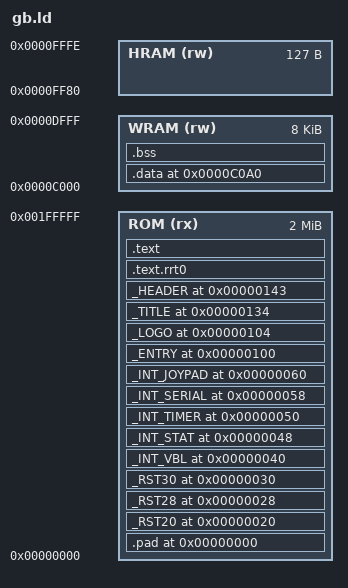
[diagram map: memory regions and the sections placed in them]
/* Game Boy (SM83) linker script for ld.lld + rrt0 */

ENTRY(_reset)

MEMORY {
    ROM  (rx) : ORIGIN = 0x0000, LENGTH = 0x200000  /* 2MB max (MBC5) */
    WRAM (rw) : ORIGIN = 0xC000, LENGTH = 0x2000
    HRAM (rw) : ORIGIN = 0xFF80, LENGTH = 0x007F
}

SECTIONS {
    .pad 0x0000 : { FILL(0xFF); . = 0x0020; } > ROM

    _RST20      (0x0020) : { KEEP(*(_RST20)) } > ROM
    _RST28      (0x0028) : { KEEP(*(_RST28)) } > ROM
    _RST30      (0x0030) : { KEEP(*(_RST30)) } > ROM

    _INT_VBL    (0x0040) : { KEEP(*(_INT_VBL)) } > ROM
    _INT_STAT   (0x0048) : { KEEP(*(_INT_STAT)) } > ROM
    _INT_TIMER  (0x0050) : { KEEP(*(_INT_TIMER)) } > ROM
    _INT_SERIAL (0x0058) : { KEEP(*(_INT_SERIAL)) } > ROM
    _INT_JOYPAD (0x0060) : { KEEP(*(_INT_JOYPAD)) } > ROM

    _ENTRY      (0x0100) : { KEEP(*(_ENTRY)) } > ROM
    _LOGO       (0x0104) : { KEEP(*(_LOGO)) } > ROM
    _TITLE      (0x0134) : { KEEP(*(_TITLE)) } > ROM
    _HEADER     (0x0143) : { KEEP(*(_HEADER)) } > ROM

    .text.rrt0 : { KEEP(*(.text.rrt0)) } > ROM

    /* Banked sections must be claimed before the resident .text glob below, as
       the linker assigns each input section to the first output section that
       matches. They carry an explicit VMA and AT(), so they leave the resident
       location counter alone; __resident_lma saves it for the .text below.
       gb_banked.ld is generated by gb-bank-pack, empty when nothing is banked,
       and found through the -L path cargo-gb passes. */
    __resident_lma = .;
    INCLUDE "gb_banked.ld"

    /* Without the explicit AT(), the preceding banked sections leave the load
       counter in a high bank and the flat binary overlaps. */
    .text __resident_lma : AT(__resident_lma) {
        *(.text .text.*)
        *(.rodata .rodata.*)
    } > ROM

    /* The LMA follows .text in bank 0, where rrt0 can reach it. */
    .data 0xC0A0 : AT(LOADADDR(.text) + SIZEOF(.text)) {
        *(.data .data.*)
        *(.data.initialized)
    } > WRAM

    /* Named by rrt0, which copies the initializers at reset. */
    s__INITIALIZER = LOADADDR(.data);
    l__INITIALIZER = SIZEOF(.data);
    s__INITIALIZED = ADDR(.data);

    .bss (NOLOAD) : {
        *(.bss .bss.*)
        *(COMMON)
    } > WRAM

    /DISCARD/ : {
        *(.comment)
        *(.eh_frame*)
        *(.debug*)
    }
}
